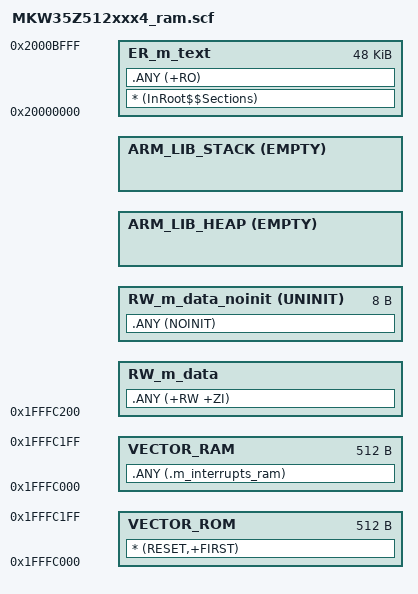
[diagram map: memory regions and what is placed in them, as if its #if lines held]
#! armcc -E
/*
** ###################################################################
**     Processor:           MKW35Z512VHT4
**     Compiler:            Keil ARM C/C++ Compiler
**     Reference manual:    MKW36A512RM Rev. 7, 07/2019
**     Version:             rev. 1.4, 2019-01-25
**     Build:               b190125
**
**     Abstract:
**         Linker file for the Keil ARM C/C++ Compiler
**
**     Copyright 2016 Freescale Semiconductor, Inc.
**     Copyright 2016-2019 NXP
**     All rights reserved.
**
**     SPDX-License-Identifier: BSD-3-Clause
**
**     http:                 www.nxp.com
**     mail:                 support@nxp.com
**
** ###################################################################
*/

#define m_interrupts_start             0x1FFFC000
#define m_interrupts_size              0x00000200

#define m_data_start                   0x1FFFC200
#define m_data_size                    0x00003E00

#define m_text_start                   0x20000000
#define m_text_size                    0x0000C000

#define m_data_noinit_size             0x00000008

/* Sizes */
#if (defined(__stack_size__))
  #define Stack_Size                   __stack_size__
#else
  #define Stack_Size                   0x0400
#endif

#if (defined(__heap_size__))
  #define Heap_Size                    __heap_size__
#else
  #define Heap_Size                    0x0400
#endif

LR_m_text m_text_start m_text_size {   ; load region size_region
  ER_m_text m_text_start m_text_size { ; load address = execution address
    * (InRoot$$Sections)
    .ANY (+RO)
  }

  RW_m_data m_data_start m_data_size-Stack_Size-Heap_Size { ; RW data
    .ANY (+RW +ZI)
  }
  RW_m_data_noinit +0 UNINIT m_data_noinit_size { ; NOINIT data
    .ANY (NOINIT)
  }
  ARM_LIB_HEAP +0 EMPTY Heap_Size {    ; Heap region growing up
  }
  ARM_LIB_STACK m_data_start+m_data_size EMPTY -Stack_Size { ; Stack region growing down
  }
}

LR_m_interrupts m_interrupts_start m_interrupts_size {
  VECTOR_ROM m_interrupts_start m_interrupts_size { ; load address = execution address
    * (RESET,+FIRST)
  }
}

LR_m_interrupts_ram m_interrupts_start m_interrupts_size {
  VECTOR_RAM m_interrupts_start m_interrupts_size { ; load address = execution address
    .ANY (.m_interrupts_ram)
  }
}

